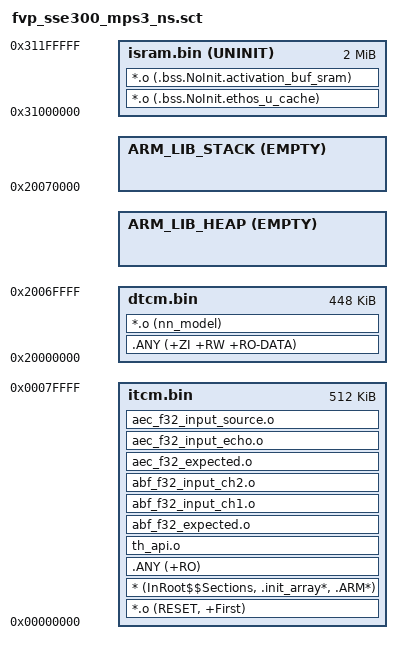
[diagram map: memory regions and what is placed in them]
; Copyright (c) 2021-2024 Arm Limited. All rights reserved.
; SPDX-License-Identifier: Apache-2.0
;
; Licensed under the Apache License, Version 2.0 (the "License");
; you may not use this file except in compliance with the License.
; You may obtain a copy of the License at
;
; http://www.apache.org/licenses/LICENSE-2.0
;
; Unless required by applicable law or agreed to in writing, software
; distributed under the License is distributed on an "AS IS" BASIS,
; WITHOUT WARRANTIES OR CONDITIONS OF ANY KIND, either express or implied.
; See the License for the specific language governing permissions and
; limitations under the License.
; *************************************************************
; ***       Scatter-Loading Description File                ***
; *************************************************************
; Note: Ethos-U NPU can access BRAM, internal SRAM and the DDR
;       sections => activation buffers and the model should
;       only be placed in those regions.
;
;---------------------------------------------------------
; First load region (ITCM)
;---------------------------------------------------------
#include "region_defs.h"

LOAD_REGION_0       0x00000000                  0x00080000
{
;-----------------------------------------------------
; First part of code mem - 512kiB
;-----------------------------------------------------
itcm.bin        0x00000000                  0x00080000
{
        *.o (RESET, +First)
        * (InRoot$$Sections, .init_array*, .ARM*)
        .ANY (+RO)
        /* different test vectors */
        th_api.o
        abf_f32_expected.o
        abf_f32_input_ch1.o
        abf_f32_input_ch2.o
        aec_f32_expected.o
        aec_f32_input_echo.o
        aec_f32_input_source.o
}

;-----------------------------------------------------
; 384kiB of 512kiB DTCM is used for any other RW or ZI
; data. Note: this region is internal to the Cortex-M
; CPU.
;-----------------------------------------------------
dtcm.bin        0x20000000                  0x00070000
{
; Any R/W and/or zero initialised data
        .ANY (+ZI +RW +RO-DATA)

; nn models default space
*.o (nn_model)

}

ARM_LIB_HEAP +0 ALIGN 8 EMPTY  HEAP_SIZE  {   ; Reserve empty region for heap
}
;-----------------------------------------------------
; 32 kiB of stack space within the DTCM region. See
; `dtcm.bin` for the first section. Note: by virtue of
; being part of DTCM, this region is only accessible
; from Cortex-M55. We use the last DTCM bank
;-----------------------------------------------------
ARM_LIB_STACK   0x20070000 EMPTY ALIGN 8    STACK_SIZE
{}

;-----------------------------------------------------
; FPGA internal SRAM of 2MiB - reserved for activation
; buffers.
; This region should have 3 cycle read latency from
; both Cortex-M55 and Ethos-U NPU
;-----------------------------------------------------
isram.bin       0x31000000  UNINIT ALIGN 16 0x00200000
{
; Cache area (if used)
*.o (.bss.NoInit.ethos_u_cache)

; activation buffers a.k.a tensor arena when
; memory mode sram only or shared sram
*.o (.bss.NoInit.activation_buf_sram)
}
}

